# ATUC256L3U device description
Architecture: AVR32_UC3; Family: AVR UC3
Registers are 32-bit, read-write, reset 0x0 unless marked. A register's access mark holds for its fields unless they carry their own. Offsets are from the block's base; [hi:lo] are bit positions; lines under a group give offsets from that group; {n}, {i} and the like mark numbered series; 'fields as' and 'values as' point back to an identical list.

## IISC — Inter-IC Sound (I2S) Controller
Instances: IISC 0xffff7800
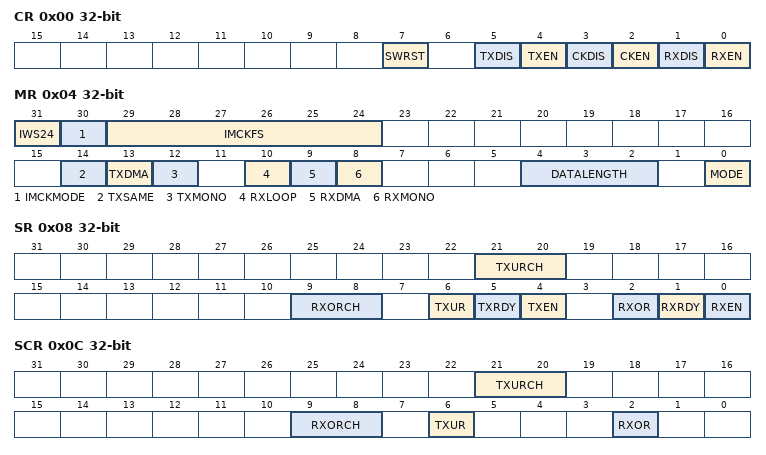
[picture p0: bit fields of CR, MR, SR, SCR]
0x00 CR wo reset not defined — Control Register
  [all] fields
    0=OFF; 1=ON
  [7] SWRST — Software Reset
  [5] TXDIS — Transmit Disable
  [4] TXEN — Transmit Enable
  [3] CKDIS — Clocks Disable
  [2] CKEN — Clocks Enable
  [1] RXDIS — Receive Disable
  [0] RXEN — Receive Enable
0x04 MR — Mode Register
  [31] IWS24 — IWS Data Slot Width
    0=32; 1=24
  [30] IMCKMODE — Master Clock Mode
    0=NO_IMCK; 1=IMCK
  [29:24] IMCKFS — Master Clock to fs Ratio
    0=16; 1=32; 3=64; 7=128; 15=256; 23=384; 31=512; 47=768; 63=1024
  [14] TXSAME — Transmit Data when Underrun
    0=ZERO; 1=SAME
  [13] TXDMA — Single or Multiple DMA Channels for Transmitter
    0=SINGLE; 1=MULTIPLE
  [12] TXMONO — Transmitter Mono
    0=STEREO; 1=MONO
  [10] RXLOOP — Loop-back Test Mode
    0=OFF; 1=ON
  [9] RXDMA — Single or Multiple DMA Channels for Receiver
    0=SINGLE; 1=MULTIPLE
  [8] RXMONO — Receiver Mono
    0=STEREO; 1=MONO
  [4:2] DATALENGTH — Data Word Length
    0=32; 1=24; 2=20; 3=18; 4=16; 5=16C; 6=8; 7=8C
  [0] MODE — Master/Slave/Controller Mode
    0=SLAVE; 1=MASTER
0x08 SR ro — Status Register
  [21:20] TXURCH — Transmit Underrun Channels
    0=LEFT; 1=RIGHT
  [9:8] RXORCH — Receive Overrun Channels
    0=LEFT; 1=RIGHT
  [6] TXUR — Transmit Underrun
    0=NO; 1=SET
  [5] TXRDY — Transmit Ready
    0=FULL; 1=EMPTY
  [4] TXEN — Transmit Enable
    0=OFF; 1=ON
  [2] RXOR — Receive Overrun
    0=NO; 1=SET
  [1] RXRDY — Receive Ready
    0=EMPTY; 1=FULL
  [0] RXEN — Receive Enable
    0=OFF; 1=ON
0x0C SCR wo reset not defined — Status Clear Register
  [21:20] TXURCH — Transmit Underrun Channels
  [9:8] RXORCH — Receive Overrun Channels
  [6] TXUR — Transmit Underrun
    0=NO; 1=SET
  [2] RXOR — Receive Overrun
    0=NO; 1=SET
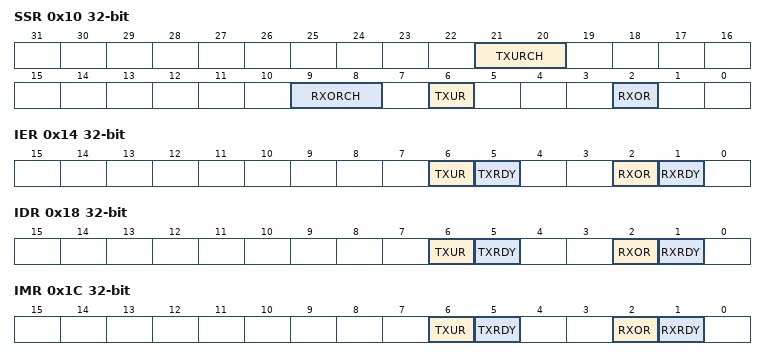
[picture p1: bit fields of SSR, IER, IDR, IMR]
0x10 SSR wo reset not defined — Status Set Register
  fields as SCR
0x14 IER wo reset not defined — Interrupt Enable Register
  [6] TXUR — Transmit Underrun Interrupt Enable
    0=NO; 1=SET
  [5] TXRDY — Transmit Ready Interrupt Enable
    0=FULL; 1=EMPTY
  [2] RXOR — Receive Overrun Interrupt Enable
    0=NO; 1=SET
  [1] RXRDY — Receiver Ready Interrupt Enable
    0=EMPTY; 1=FULL
0x18 IDR wo reset not defined — Interrupt Disable Register
  [6] TXUR — Transmit Underrun Interrupt Disable
    0=NO; 1=SET
  [5] TXRDY — Transmit Ready Interrupt Disable
    0=FULL; 1=EMPTY
  [2] RXOR — Receive Overrun Interrupt Disable
    0=NO; 1=SET
  [1] RXRDY — Receive Ready Interrupt Disable
    0=EMPTY; 1=FULL
0x1C IMR ro — Interrupt Mask Register
  [6] TXUR — Transmit Underrun Interrupt Mask
    0=NO; 1=SET
  [5] TXRDY — Transmit Ready Interrupt Mask
    0=FULL; 1=EMPTY
  [2] RXOR — Receive Overrun Interrupt Mask
    0=NO; 1=SET
  [1] RXRDY — Receive Ready Interrupt Mask
    0=EMPTY; 1=FULL
0x20 RHR ro — Receive Holding Register
  [31:0] RDAT — Receive Data
0x24 THR wo reset not defined — Transmit Holding Register
  [31:0] TDAT — Transmit Data
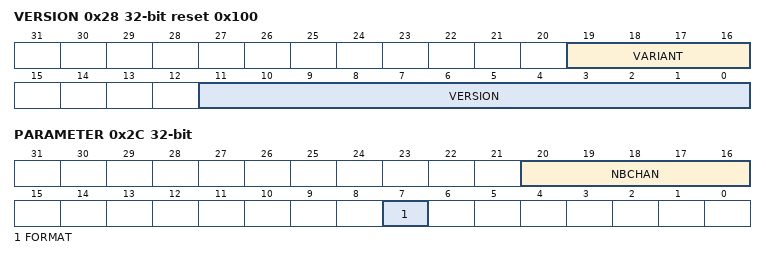
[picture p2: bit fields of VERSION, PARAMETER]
0x28 VERSION ro reset 0x100
  [19:16] VARIANT — Reserved. Value subject to change. No functionality associated.
  [11:0] VERSION — Reserved. Value subject to change. No functionality associated. This is the Atmel internal version of the macrocell.
0x2C PARAMETER ro reset not defined
  [20:16] NBCHAN — Maximum number of channels - 1
  [7] FORMAT — Data protocol format
    0=I2S

## PDCA — Peripheral DMA Controller
Instances: PDCA 0xffff0000
{0x0+0x40*i} channel[{i}] (i=0..31) group
  0x00 MAR — Memory Address Register
    [31:0] MADDR — Memory Address
  0x04 PSR reset not defined — Peripheral Select Register
    [7:0] PID — Peripheral Identifier
  0x08 TCR — Transfer Counter Register
    [15:0] TCV — Transfer Counter Value
  0x0C MARR — Memory Address Reload Register
    [31:0] MARV — Memory Address Reload Value
  0x10 TCRR — Transfer Counter Reload Register
    [15:0] TCRV — Transfer Counter Reload Value
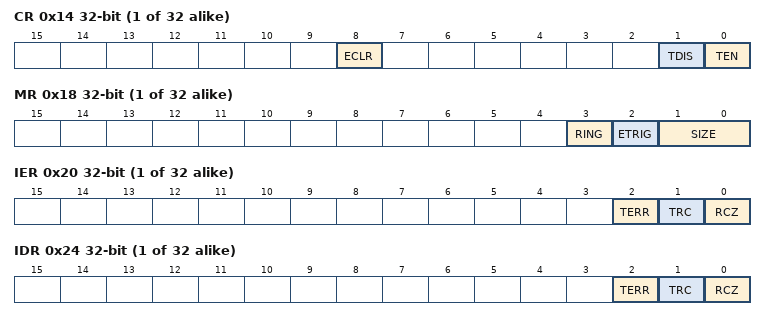
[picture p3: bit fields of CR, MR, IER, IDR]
  0x14 CR wo — Control Register
    [8] ECLR — Error Clear
    [1] TDIS — Transfer Disable
    [0] TEN — Transfer Enable
  0x18 MR — Mode Register
    [3] RING — Ring Buffer
    [2] ETRIG — Event trigger
    [1:0] SIZE — Transfer size
      0=Byte; 1=Half_Word; 2=Word
  0x1C SR ro — Status Register
    [0] TEN — Transfer Enabled
  0x20 IER wo — Interrupt Enable Register
    [2] TERR — Transfer Error
    [1] TRC — Transfer Complete
    [0] RCZ — Reload Counter Zero
  0x24 IDR wo — Interrupt Disable Register
    fields as channel[0].IER
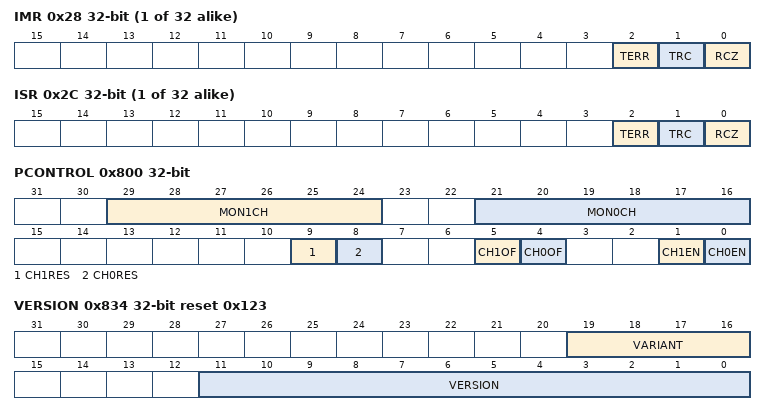
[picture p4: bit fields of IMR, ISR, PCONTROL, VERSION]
  0x28 IMR ro — Interrupt Mask Register
    fields as channel[0].IER
  0x2C ISR ro — Interrupt Status Register
    fields as channel[0].IER
0x800 PCONTROL — Performance Control Register
  [29:24] MON1CH — PDCA Channel to monitor with counter 1
  [21:16] MON0CH — PDCA Channel to monitor with counter 0
  [9] CH1RES — Channel 1 counter reset
  [8] CH0RES — Channel 0 counter reset
  [5] CH1OF — Channel 1 overflow freeze
  [4] CH0OF — Channel 0 Overflow Freeze
  [1] CH1EN — Channel 1 Enabled.
  [0] CH0EN — Channel 0 Enabled
0x804 PRDATA0 ro — Channel 0 Read Data Cycles
  [31:0] DATA — Data Cycles Counted Since Last reset
0x808 PRSTALL0 ro — Channel 0 Read Stall Cycles
  [31:0] STALL — Stall Cycles counted since last reset
0x80C PRLAT0 ro — Channel 0 Read Max Latency
  [15:0] LAT — Maximum Transfer Initiation cycles counted since last reset
0x810 PWDATA0 ro — Channel 0 Write Data Cycles
  [31:0] DATA — Data Cycles Counted since last Reset
0x814 PWSTALL0 ro — Channel 0 Write Stall Cycles
  [31:0] STALL — Stall cycles counted since last reset
0x818 PWLAT0 ro — Channel0 Write Max Latency
  [15:0] LAT — Maximum transfer initiation cycles counted since last reset
0x81C PRDATA1 ro — Channel 1 Read Data Cycles
  [31:0] DATA — Data Cycles Counted Since Last reset
0x820 PRSTALL1 ro — Channel Read Stall Cycles
  [31:0] STALL — Stall Cycles Counted since last reset
0x824 PRLAT1 ro — Channel 1 Read Max Latency
  [15:0] LAT — Maximum Transfer initiation cycles counted since last reset
0x828 PWDATA1 ro — Channel 1 Write Data Cycles
  [31:0] DATA — Data cycles Counted Since last reset
0x82C PWSTALL1 ro — Channel 1 Write stall Cycles
  [31:0] STALL — Stall cycles counted since last reset
0x830 PWLAT1 ro — Channel 1 Read Max Latency
  fields as PWLAT0
0x834 VERSION ro reset 0x123
  [19:16] VARIANT — Variant Number
  [11:0] VERSION — Version Number
